# STM32H523 register map
File version: 1.2
CPU: CM33 r0p0, little endian, MPU, FPU, 4 interrupt priority bits
Registers are 32-bit, read-write, reset 0x0 unless marked. A register's access mark holds for its fields unless they carry their own. Offsets are from the block's base; [hi:lo] are bit positions.

## UCPD1 — UCPD register block
Base 0x4000DC00
Same registers: UCPD1_S 0x5000DC00
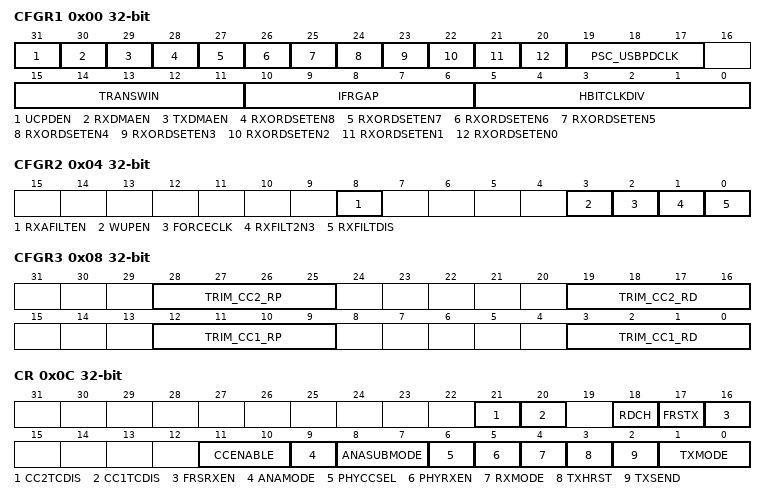
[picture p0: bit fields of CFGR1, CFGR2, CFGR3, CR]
0x00 CFGR1 — UCPD configuration register 1
  [31] UCPDEN — UCPD peripheral enable
  [30] RXDMAEN — Reception DMA mode enable
  [29] TXDMAEN — Transmission DMA mode enable
  [28] RXORDSETEN8 — SOP extension #2
  [27] RXORDSETEN7 — SOP extension #1
  [26] RXORDSETEN6 — SOP'' Debug
  [25] RXORDSETEN5 — SOP'_Debug
  [24] RXORDSETEN4 — Cable Detect reset
  [23] RXORDSETEN3 — Hard Reset detection
  [22] RXORDSETEN2 — SOP'' detection
  [21] RXORDSETEN1 — SOP' detection
  [20] RXORDSETEN0 — SOP detection
  [19:17] PSC_USBPDCLK — Pre-scaler division ratio for generating ucpd_clk
  [15:11] TRANSWIN — Transition window duration
  [10:6] IFRGAP — Division ratio for producing inter-frame gap timer clock
  [5:0] HBITCLKDIV — Division ratio for producing half-bit clock
0x04 CFGR2 — UCPD configuration register 2
  [8] RXAFILTEN — Rx analog filter enable
  [3] WUPEN — Wake-up from Stop mode enable
  [2] FORCECLK — Force ClkReq clock request
  [1] RXFILT2N3 — BMC decoder Rx pre-filter sampling method
  [0] RXFILTDIS — BMC decoder Rx pre-filter enable
0x08 CFGR3 — UCPD configuration register 3
  [28:25] TRIM_CC2_RP — SW trim value for Rp current sources on the CC2 line
  [19:16] TRIM_CC2_RD — SW trim value for Rd resistor on the CC2 line
  [12:9] TRIM_CC1_RP — SW trim value for Rp current sources on the CC1 line
  [3:0] TRIM_CC1_RD — SW trim value for Rd resistor on the CC1 line
0x0C CR — UCPD control register
  [21] CC2TCDIS — CC2 Type-C detector disable
  [20] CC1TCDIS — CC1 Type-C detector disable
  [18] RDCH — Rdch condition drive
  [17] FRSTX — FRS Tx signaling enable.
  [16] FRSRXEN — FRS event detection enable
  [11:10] CCENABLE — CC line enable
  [9] ANAMODE — Analog PHY operating mode
  [8:7] ANASUBMODE — Analog PHY sub-mode
  [6] PHYCCSEL — CC1/CC2 line selector for USB Power Delivery signaling
  [5] PHYRXEN — USB Power Delivery receiver enable
  [4] RXMODE — Receiver mode
  [3] TXHRST — Command to send a Tx Hard Reset
  [2] TXSEND — Command to send a Tx packet
  [1:0] TXMODE — Type of Tx packet
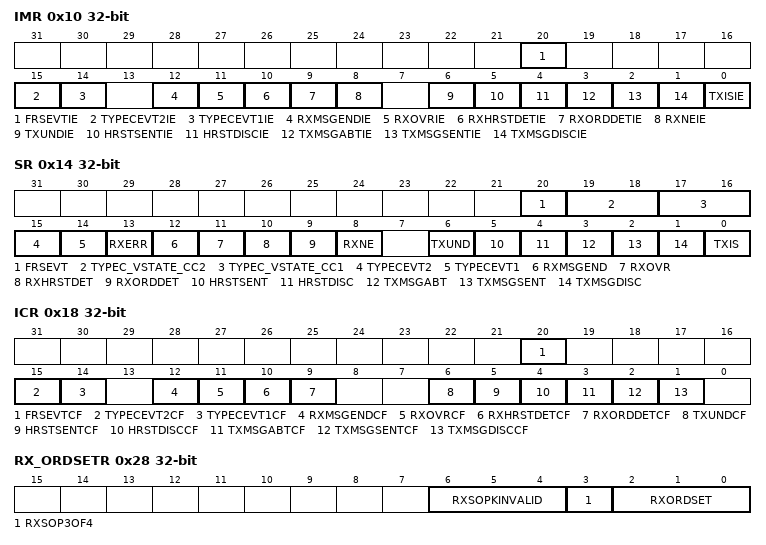
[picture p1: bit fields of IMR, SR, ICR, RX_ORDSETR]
0x10 IMR — UCPD interrupt mask register
  [20] FRSEVTIE ro — FRSEVT interrupt enable
  [15] TYPECEVT2IE — TYPECEVT2 interrupt enable
  [14] TYPECEVT1IE — TYPECEVT1 interrupt enable
  [12] RXMSGENDIE — RXMSGEND interrupt enable
  [11] RXOVRIE — RXOVR interrupt enable
  [10] RXHRSTDETIE — RXHRSTDET interrupt enable
  [9] RXORDDETIE — RXORDDET interrupt enable
  [8] RXNEIE — RXNE interrupt enable
  [6] TXUNDIE — TXUND interrupt enable
  [5] HRSTSENTIE — HRSTSENT interrupt enable
  [4] HRSTDISCIE — HRSTDISC interrupt enable
  [3] TXMSGABTIE — TXMSGABT interrupt enable
  [2] TXMSGSENTIE — TXMSGSENT interrupt enable
  [1] TXMSGDISCIE — TXMSGDISC interrupt enable
  [0] TXISIE — TXIS interrupt enable
0x14 SR ro — UCPD status register
  [20] FRSEVT — FRS detection event
  [19:18] TYPEC_VSTATE_CC2 — CC2 line voltage level
  [17:16] TYPEC_VSTATE_CC1 — The status bitfield indicates the voltage level on the CC1 line in its steady state.
  [15] TYPECEVT2 — Type-C voltage level event on CC2 line
  [14] TYPECEVT1 — Type-C voltage level event on CC1 line
  [13] RXERR — Receive message error
  [12] RXMSGEND — Rx message received
  [11] RXOVR — Rx data overflow detection
  [10] RXHRSTDET — Rx Hard Reset receipt detection
  [9] RXORDDET — Rx ordered set (4 K-codes) detection
  [8] RXNE — Receive data register not empty detection
  [6] TXUND — Tx data underrun detection
  [5] HRSTSENT — Hard Reset message sent
  [4] HRSTDISC — Hard Reset discarded
  [3] TXMSGABT — Transmit message abort
  [2] TXMSGSENT — Message transmission completed
  [1] TXMSGDISC — Message transmission discarded
  [0] TXIS — Transmit interrupt status
0x18 ICR wo — UCPD interrupt clear register
  [20] FRSEVTCF — FRS event flag (FRSEVT) clear
  [15] TYPECEVT2CF — Type-C CC2 line event flag (TYPECEVT2) clear
  [14] TYPECEVT1CF — Type-C CC1 event flag (TYPECEVT1) clear
  [12] RXMSGENDCF — Rx message received flag (RXMSGEND) clear
  [11] RXOVRCF — Rx overflow flag (RXOVR) clear
  [10] RXHRSTDETCF — Rx Hard Reset detect flag (RXHRSTDET) clear
  [9] RXORDDETCF — Rx ordered set detect flag (RXORDDET) clear
  [6] TXUNDCF — Tx underflow flag (TXUND) clear
  [5] HRSTSENTCF — Hard reset send flag (HRSTSENT) clear
  [4] HRSTDISCCF — Hard reset discard flag (HRSTDISC) clear
  [3] TXMSGABTCF — Tx message abort flag (TXMSGABT) clear
  [2] TXMSGSENTCF — Tx message send flag (TXMSGSENT) clear
  [1] TXMSGDISCCF — Tx message discard flag (TXMSGDISC) clear
0x1C TX_ORDSETR — UCPD Tx ordered set type register
  [19:0] TXORDSET — Ordered set to transmit
0x20 TX_PAYSZR — UCPD Tx payload size register
  [9:0] TXPAYSZ — Payload size yet to transmit
0x24 TXDR — UCPD Tx data register
  [7:0] TXDATA — Data byte to transmit
0x28 RX_ORDSETR ro — UCPD Rx ordered set register
  [6:4] RXSOPKINVALID — The bitfield is for debug purposes only.
  [3] RXSOP3OF4 — The bit indicates the number of correct K-codes.
  [2:0] RXORDSET — Rx ordered set code detected
0x2C RX_PAYSZR ro — UCPD Rx payload size register
  [9:0] RXPAYSZ — Rx payload size received
0x30 RXDR ro — UCPD receive data register
  [7:0] RXDATA — Data byte received
0x34 RX_ORDEXTR1 — UCPD Rx ordered set extension register 1
  [19:0] RXSOPX1 — Ordered set 1 received
0x38 RX_ORDEXTR2 — UCPD Rx ordered set extension register 2
  [19:0] RXSOPX2 — Ordered set 2 received
